# ATmega3209 register map
Vendor: Atmel; File version: 1.0
CPU: other r0p0, little endian, no MPU, no FPU, 4 interrupt priority bits
Registers are 8-bit, read-write, reset 0x0 unless marked. A register's access mark holds for its fields unless they carry their own. Offsets are from the block's base; [hi:lo] are bit positions; {n}, {i} and the like mark numbered series.

## SIGROW — Signature row
Base 0x00001100
{0x0+i} DEVICEID{i} ro (i=0..2) — Device ID Byte {i}
{0x3+i} SERNUM{i} ro (i=0..9) — Serial Number Byte {i}
0x14 OSCCAL32K ro — Oscillator Calibration for 32kHz ULP
0x18 OSCCAL16M0 ro — Oscillator Calibration 16 MHz Byte 0
0x19 OSCCAL16M1 ro — Oscillator Calibration 16 MHz Byte 1
0x1A OSCCAL20M0 ro — Oscillator Calibration 20 MHz Byte 0
0x1B OSCCAL20M1 ro — Oscillator Calibration 20 MHz Byte 1
0x20 TEMPSENSE0 ro — Temperature Sensor Calibration Byte 0
0x21 TEMPSENSE1 ro — Temperature Sensor Calibration Byte 1
0x22 OSC16ERR3V ro — OSC16 error at 3V
0x23 OSC16ERR5V ro — OSC16 error at 5V
0x24 OSC20ERR3V ro — OSC20 error at 3V
0x25 OSC20ERR5V ro — OSC20 error at 5V
0x2F CHECKSUM1 ro — CRC Checksum Byte 1

## SLPCTRL — Sleep Controller
Base 0x00000050
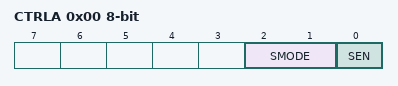
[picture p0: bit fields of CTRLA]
0x00 CTRLA — Control
  [2:1] SMODE — Sleep mode
    0=IDLE (Idle mode); 1=STDBY (Standby Mode); 2=PDOWN (Power-down Mode)
  [0] SEN — Sleep enable

## SPI0 — Serial Peripheral Interface
Base 0x000008C0
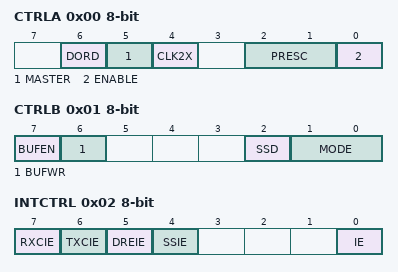
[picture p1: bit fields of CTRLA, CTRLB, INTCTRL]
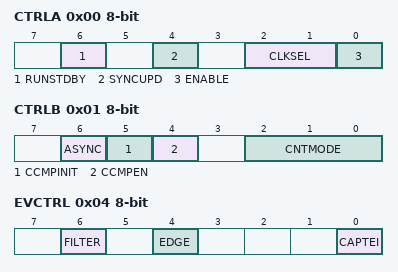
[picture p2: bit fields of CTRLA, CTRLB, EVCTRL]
0x00 CTRLA — Control A
  [6] DORD — Data Order Setting
  [5] MASTER — Master Operation Enable
  [4] CLK2X — Enable Double Speed
  [2:1] PRESC — Prescaler
    0=DIV4 (System Clock / 4); 1=DIV16 (System Clock / 16); 2=DIV64 (System Clock / 64); 3=DIV128 (System Clock / 128)
  [0] ENABLE — Enable Module
0x01 CTRLB — Control B
  [7] BUFEN — Buffer Mode Enable
  [6] BUFWR — Buffer Write Mode
  [2] SSD — Slave Select Disable
  [1:0] MODE — SPI Mode
    {v}=SPI Mode {v} (v=0..3)
0x02 INTCTRL — Interrupt Control
  [7] RXCIE — Receive Complete Interrupt Enable
  [6] TXCIE — Transfer Complete Interrupt Enable
  [5] DREIE — Data Register Empty Interrupt Enable
  [4] SSIE — Slave Select Trigger Interrupt Enable
  [0] IE — Interrupt Enable
0x03 INTFLAGS — Interrupt Flags
  [7] BUFFERED_RXCIF — Receive Complete Interrupt Flag
  [7] DEFAULT_IF — Interrupt Flag
  [6] BUFFERED_TXCIF — Transfer Complete Interrupt Flag
  [6] DEFAULT_WRCOL — Write Collision
  [5] BUFFERED_DREIF — Data Register Empty Interrupt Flag
  [4] BUFFERED_SSIF — Slave Select Trigger Interrupt Flag
  [0] BUFFERED_BUFOVF — Buffer Overflow
0x04 DATA

## SYSCFG — System Configuration Registers
Base 0x00000F01
0x00 REVID — Revision ID
0x01 EXTBRK — External Break
  [0] ENEXTBRK — External break enable
0x17 OCDM — OCD Message Register
0x18 OCDMS — OCD Message Status
  [0] OCDMR — OCD Message Read

## TCB0 — 16-bit Timer Type B
Base 0x00000A80
Same registers: TCB1 0x00000A90, TCB2 0x00000AA0, TCB3 0x00000AB0
0x00 CTRLA — Control A
  [6] RUNSTDBY — Run Standby
  [4] SYNCUPD — Synchronize Update
  [2:1] CLKSEL — Clock Select
    0=CLKDIV1 (CLK_PER (No Prescaling)); 1=CLKDIV2 (CLK_PER/2 (From Prescaler)); 2=CLKTCA (Use Clock from TCA)
  [0] ENABLE
0x01 CTRLB — Control Register B
  [6] ASYNC — Asynchronous Enable
  [5] CCMPINIT — Pin Initial State
  [4] CCMPEN — Pin Output Enable
  [2:0] CNTMODE — Timer Mode
    0=INT (Periodic Interrupt); 1=TIMEOUT (Periodic Timeout); 2=CAPT (Input Capture Event); 3=FRQ (Input Capture Frequency measurement); 4=PW (Input Capture Pulse-Width measurement); 5=FRQPW (Input Capture Frequency and Pulse-Width measurement); 6=SINGLE (Single Shot); 7=PWM8 (8-bit PWM)
0x04 EVCTRL — Event Control
  [6] FILTER — Input Capture Noise Cancellation Filter
  [4] EDGE — Event Edge
  [0] CAPTEI — Event Input Enable
0x05 INTCTRL — Interrupt Control
  [0] CAPT — Capture or Timeout
0x06 INTFLAGS — Interrupt Flags
  [0] CAPT — Capture or Timeout
0x07 STATUS ro
  [0] RUN
0x08 DBGCTRL — Debug Control
  [0] DBGRUN — Debug Run
0x09 TEMP — Temporary Value
0x0A CNT 16-bit (reset mask 0xFF) — Count
0x0C CCMP 16-bit (reset mask 0xFF) — Compare or Capture
